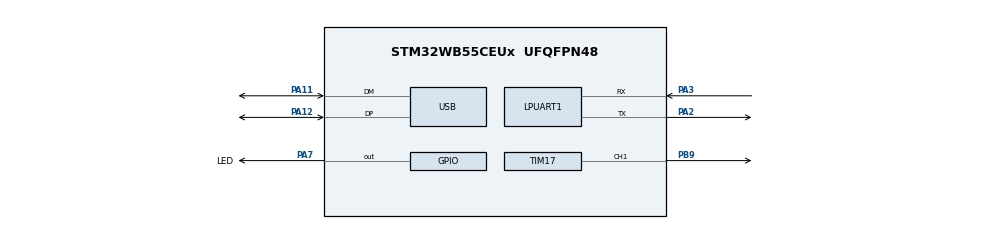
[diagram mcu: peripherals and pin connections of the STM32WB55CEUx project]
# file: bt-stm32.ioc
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Mcu.Family=STM32WB
Mcu.Name=STM32WB55CEUx
Mcu.Package=UFQFPN48
NVIC.PriorityGroup=NVIC_PRIORITYGROUP_4
OSC_IN.Mode=HSE-External-Oscillator
OSC_IN.Signal=RCC_OSC_IN
OSC_OUT.Mode=HSE-External-Oscillator
OSC_OUT.Signal=RCC_OSC_OUT
PA11.Mode=Device
PA11.Signal=USB_DM
PA12.Mode=Device
PA12.Signal=USB_DP
PA13.Mode=Trace_Asynchronous_SW
PA13.Signal=SYS_JTMS-SWDIO
PA14.Mode=Trace_Asynchronous_SW
PA14.Signal=SYS_JTCK-SWCLK
PA2.Mode=Asynchronous
PA2.Signal=LPUART1_TX
PA3.Mode=Asynchronous
PA3.Signal=LPUART1_RX
PA7.GPIO_Label=LED
PA7.Signal=GPIO_Output
PB3.Mode=Trace_Asynchronous_SW
PB3.Signal=SYS_JTDO-SWO
PB9.Signal=S_TIM17_CH1
PC14-OSC32_IN.Mode=LSE-External-Oscillator
PC14-OSC32_IN.Signal=RCC_OSC32_IN
PC15-OSC32_OUT.Mode=LSE-External-Oscillator
PC15-OSC32_OUT.Signal=RCC_OSC32_OUT
ProjectManager.HeapSize=0x200
ProjectManager.StackSize=0x400
ProjectManager.TargetToolchain=CMake
RCC.ADCFreq_Value=48000000
RCC.AHB2CLKDivider=RCC_SYSCLK_DIV2
RCC.AHBFreq_Value=64000000
RCC.APB1Freq_Value=64000000
RCC.APB1TimFreq_Value=64000000
RCC.APB2Freq_Value=64000000
RCC.APB2TimFreq_Value=64000000
RCC.APB3Freq_Value=4000000
RCC.Cortex2_Div=SYSTICK_CLKSOURCE_HCLK_DIV8
RCC.CortexFreq_Value=64000000
RCC.HCLKFreq_Value=64000000
RCC.HSE_VALUE=8000000
RCC.HSI48_VALUE=48000000
RCC.HSI_VALUE=16000000
RCC.PLLN=32
RCC.PLLSAI1N=24
RCC.SYSCLKFreq_VALUE=64000000
RCC.SYSCLKSource=RCC_SYSCLKSOURCE_PLLCLK
RCC.USBFreq_Value=48000000
RCC.VCOOutputFreq_Value=128000000
SH.S_TIM17_CH1.0=TIM17_CH1,PWM Generation1 CH1
TIM17.Channel=TIM_CHANNEL_1
VP_MEMORYMAP_VS_MEMORYMAP.Mode=CurAppReg
VP_TIM17_VS_ClockSourceINT.Mode=Enable_Timer
board=custom

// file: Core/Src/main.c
/* USER CODE BEGIN Header */
/**
  ******************************************************************************
  * @file           : main.c
  * @brief          : Main program body
  ******************************************************************************
  * @attention
  *
  * Copyright (c) 2026 STMicroelectronics.
  * All rights reserved.
  *
  * This software is licensed under terms that can be found in the LICENSE file
  * in the root directory of this software component.
  * If no LICENSE file comes with this software, it is provided AS-IS.
  *
  ******************************************************************************
  */
/* USER CODE END Header */
#include "main.h"

UART_HandleTypeDef hlpuart1;

TIM_HandleTypeDef htim17;

PCD_HandleTypeDef hpcd_USB_FS;

void SystemClock_Config(void);
void PeriphCommonClock_Config(void);
static void MX_GPIO_Init(void);
static void MX_USB_PCD_Init(void);
static void MX_LPUART1_UART_Init(void);
static void MX_TIM17_Init(void);

const uint16_t LED_PORT = GPIOA;
const uint16_t LED_PIN = GPIO_PIN_7;

int main(void)
{

  /* MCU Configuration--------------------------------------------------------*/

  /* Reset of all peripherals, Initializes the Flash interface and the Systick. */
  HAL_Init();

  /* Configure the system clock */
  SystemClock_Config();

  /* Configure the peripherals common clocks */
  PeriphCommonClock_Config();

  /* Initialize all configured peripherals */
  MX_GPIO_Init();
  MX_USB_PCD_Init();
  MX_LPUART1_UART_Init();
  MX_TIM17_Init();

  /* Infinite loop */
  while (1)
  {

    /* USER CODE BEGIN 3 */
    HAL_GPIO_TogglePin(LED_PORT, LED_PIN);
    HAL_Delay(500);
  }
  /* USER CODE END 3 */
}

void SystemClock_Config(void)
{
  RCC_OscInitTypeDef RCC_OscInitStruct = {0};
  RCC_ClkInitTypeDef RCC_ClkInitStruct = {0};

  /** Configure LSE Drive Capability
  */
  HAL_PWR_EnableBkUpAccess();
  __HAL_RCC_LSEDRIVE_CONFIG(RCC_LSEDRIVE_MEDIUMHIGH);

  /** Configure the main internal regulator output voltage
  */
  __HAL_PWR_VOLTAGESCALING_CONFIG(PWR_REGULATOR_VOLTAGE_SCALE1);

  /** Initializes the RCC Oscillators according to the specified parameters
  * in the RCC_OscInitTypeDef structure.
  */
  RCC_OscInitStruct.OscillatorType = RCC_OSCILLATORTYPE_HSI|RCC_OSCILLATORTYPE_HSE
                              |RCC_OSCILLATORTYPE_LSE|RCC_OSCILLATORTYPE_MSI;
  RCC_OscInitStruct.HSEState = RCC_HSE_ON;
  RCC_OscInitStruct.LSEState = RCC_LSE_ON;
  RCC_OscInitStruct.HSIState = RCC_HSI_ON;
  RCC_OscInitStruct.MSIState = RCC_MSI_ON;
  RCC_OscInitStruct.HSICalibrationValue = RCC_HSICALIBRATION_DEFAULT;
  RCC_OscInitStruct.MSICalibrationValue = RCC_MSICALIBRATION_DEFAULT;
  RCC_OscInitStruct.MSIClockRange = RCC_MSIRANGE_6;
  RCC_OscInitStruct.PLL.PLLState = RCC_PLL_ON;
  RCC_OscInitStruct.PLL.PLLSource = RCC_PLLSOURCE_MSI;
  RCC_OscInitStruct.PLL.PLLM = RCC_PLLM_DIV1;
  RCC_OscInitStruct.PLL.PLLN = 32;
  RCC_OscInitStruct.PLL.PLLP = RCC_PLLP_DIV2;
  RCC_OscInitStruct.PLL.PLLR = RCC_PLLR_DIV2;
  RCC_OscInitStruct.PLL.PLLQ = RCC_PLLQ_DIV2;
  if (HAL_RCC_OscConfig(&RCC_OscInitStruct) != HAL_OK)
  {
    Error_Handler();
  }

  /** Configure the SYSCLKSource, HCLK, PCLK1 and PCLK2 clocks dividers
  */
  RCC_ClkInitStruct.ClockType = RCC_CLOCKTYPE_HCLK4|RCC_CLOCKTYPE_HCLK2
                              |RCC_CLOCKTYPE_HCLK|RCC_CLOCKTYPE_SYSCLK
                              |RCC_CLOCKTYPE_PCLK1|RCC_CLOCKTYPE_PCLK2;
  RCC_ClkInitStruct.SYSCLKSource = RCC_SYSCLKSOURCE_PLLCLK;
  RCC_ClkInitStruct.AHBCLKDivider = RCC_SYSCLK_DIV1;
  RCC_ClkInitStruct.APB1CLKDivider = RCC_HCLK_DIV1;
  RCC_ClkInitStruct.APB2CLKDivider = RCC_HCLK_DIV1;
  RCC_ClkInitStruct.AHBCLK2Divider = RCC_SYSCLK_DIV2;
  RCC_ClkInitStruct.AHBCLK4Divider = RCC_SYSCLK_DIV1;

  if (HAL_RCC_ClockConfig(&RCC_ClkInitStruct, FLASH_LATENCY_3) != HAL_OK)
  {
    Error_Handler();
  }

  /** Enable MSI Auto calibration
  */
  HAL_RCCEx_EnableMSIPLLMode();
}

void PeriphCommonClock_Config(void)
{
  RCC_PeriphCLKInitTypeDef PeriphClkInitStruct = {0};

  /** Initializes the peripherals clock
  */
  PeriphClkInitStruct.PeriphClockSelection = RCC_PERIPHCLK_SMPS;
  PeriphClkInitStruct.SmpsClockSelection = RCC_SMPSCLKSOURCE_HSI;
  PeriphClkInitStruct.SmpsDivSelection = RCC_SMPSCLKDIV_RANGE1;

  if (HAL_RCCEx_PeriphCLKConfig(&PeriphClkInitStruct) != HAL_OK)
  {
    Error_Handler();
  }
}

static void MX_LPUART1_UART_Init(void)
{

  hlpuart1.Instance = LPUART1;
  hlpuart1.Init.BaudRate = 209700;
  hlpuart1.Init.WordLength = UART_WORDLENGTH_8B;
  hlpuart1.Init.StopBits = UART_STOPBITS_1;
  hlpuart1.Init.Parity = UART_PARITY_NONE;
  hlpuart1.Init.Mode = UART_MODE_TX_RX;
  hlpuart1.Init.HwFlowCtl = UART_HWCONTROL_NONE;
  hlpuart1.Init.OneBitSampling = UART_ONE_BIT_SAMPLE_DISABLE;
  hlpuart1.Init.ClockPrescaler = UART_PRESCALER_DIV1;
  hlpuart1.AdvancedInit.AdvFeatureInit = UART_ADVFEATURE_NO_INIT;
  hlpuart1.FifoMode = UART_FIFOMODE_DISABLE;
  if (HAL_UART_Init(&hlpuart1) != HAL_OK)
  {
    Error_Handler();
  }
  if (HAL_UARTEx_SetTxFifoThreshold(&hlpuart1, UART_TXFIFO_THRESHOLD_1_8) != HAL_OK)
  {
    Error_Handler();
  }
  if (HAL_UARTEx_SetRxFifoThreshold(&hlpuart1, UART_RXFIFO_THRESHOLD_1_8) != HAL_OK)
  {
    Error_Handler();
  }
  if (HAL_UARTEx_DisableFifoMode(&hlpuart1) != HAL_OK)
  {
    Error_Handler();
  }

}

static void MX_TIM17_Init(void)
{

  TIM_OC_InitTypeDef sConfigOC = {0};
  TIM_BreakDeadTimeConfigTypeDef sBreakDeadTimeConfig = {0};

  htim17.Instance = TIM17;
  htim17.Init.Prescaler = 0;
  htim17.Init.CounterMode = TIM_COUNTERMODE_UP;
  htim17.Init.Period = 65535;
  htim17.Init.ClockDivision = TIM_CLOCKDIVISION_DIV1;
  htim17.Init.RepetitionCounter = 0;
  htim17.Init.AutoReloadPreload = TIM_AUTORELOAD_PRELOAD_DISABLE;
  if (HAL_TIM_Base_Init(&htim17) != HAL_OK)
  {
    Error_Handler();
  }
  if (HAL_TIM_PWM_Init(&htim17) != HAL_OK)
  {
    Error_Handler();
  }
  sConfigOC.OCMode = TIM_OCMODE_PWM1;
  sConfigOC.Pulse = 0;
  sConfigOC.OCPolarity = TIM_OCPOLARITY_HIGH;
  sConfigOC.OCNPolarity = TIM_OCNPOLARITY_HIGH;
  sConfigOC.OCFastMode = TIM_OCFAST_DISABLE;
  sConfigOC.OCIdleState = TIM_OCIDLESTATE_RESET;
  sConfigOC.OCNIdleState = TIM_OCNIDLESTATE_RESET;
  if (HAL_TIM_PWM_ConfigChannel(&htim17, &sConfigOC, TIM_CHANNEL_1) != HAL_OK)
  {
    Error_Handler();
  }
  sBreakDeadTimeConfig.OffStateRunMode = TIM_OSSR_DISABLE;
  sBreakDeadTimeConfig.OffStateIDLEMode = TIM_OSSI_DISABLE;
  sBreakDeadTimeConfig.LockLevel = TIM_LOCKLEVEL_OFF;
  sBreakDeadTimeConfig.DeadTime = 0;
  sBreakDeadTimeConfig.BreakState = TIM_BREAK_DISABLE;
  sBreakDeadTimeConfig.BreakPolarity = TIM_BREAKPOLARITY_HIGH;
  sBreakDeadTimeConfig.BreakFilter = 0;
  sBreakDeadTimeConfig.AutomaticOutput = TIM_AUTOMATICOUTPUT_DISABLE;
  if (HAL_TIMEx_ConfigBreakDeadTime(&htim17, &sBreakDeadTimeConfig) != HAL_OK)
  {
    Error_Handler();
  }
  HAL_TIM_MspPostInit(&htim17);

}

static void MX_USB_PCD_Init(void)
{

  hpcd_USB_FS.Instance = USB;
  hpcd_USB_FS.Init.dev_endpoints = 8;
  hpcd_USB_FS.Init.speed = PCD_SPEED_FULL;
  hpcd_USB_FS.Init.phy_itface = PCD_PHY_EMBEDDED;
  hpcd_USB_FS.Init.Sof_enable = DISABLE;
  hpcd_USB_FS.Init.low_power_enable = DISABLE;
  hpcd_USB_FS.Init.lpm_enable = DISABLE;
  hpcd_USB_FS.Init.battery_charging_enable = DISABLE;
  if (HAL_PCD_Init(&hpcd_USB_FS) != HAL_OK)
  {
    Error_Handler();
  }

}

static void MX_GPIO_Init(void)
{
  GPIO_InitTypeDef GPIO_InitStruct = {0};

  /* GPIO Ports Clock Enable */
  __HAL_RCC_GPIOC_CLK_ENABLE();
  __HAL_RCC_GPIOB_CLK_ENABLE();
  __HAL_RCC_GPIOA_CLK_ENABLE();

  /*Configure GPIO pin Output Level */
  HAL_GPIO_WritePin(LED_GPIO_Port, LED_Pin, GPIO_PIN_RESET);

  /*Configure GPIO pin : LED_Pin */
  GPIO_InitStruct.Pin = LED_Pin;
  GPIO_InitStruct.Mode = GPIO_MODE_OUTPUT_PP;
  GPIO_InitStruct.Pull = GPIO_NOPULL;
  GPIO_InitStruct.Speed = GPIO_SPEED_FREQ_LOW;
  HAL_GPIO_Init(LED_GPIO_Port, &GPIO_InitStruct);

}

void Error_Handler(void)
{
  __disable_irq();
  while (1)
  {
  }
}
